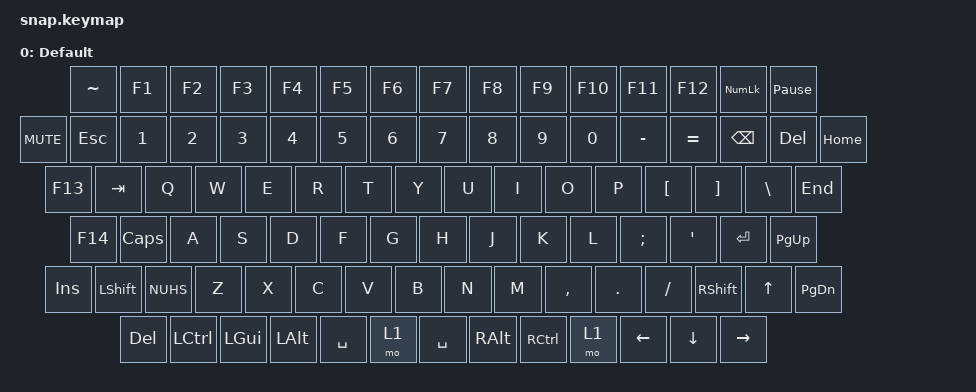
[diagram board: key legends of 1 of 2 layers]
/*
 * Copyright (c) 2022 The ZMK Contributors
 *
 * SPDX-License-Identifier: MIT
 */

#include <behaviors.dtsi>
#include <dt-bindings/zmk/keys.h>
#include <dt-bindings/zmk/rgb.h>
#include <dt-bindings/zmk/rgb.h>

/ {
    sensors {
        compatible = "zmk,keymap-sensors";
        sensors = <&left_encoder &right_encoder>;
    };

      behaviors {
        gresc: grave_escape {
            compatible = "zmk,behavior-mod-morph";
            label = "GRAVE_ESCAPE";
            #binding-cells = <0>;
            bindings = <&kp ESC>, <&kp GRAVE>;
            mods = <(MOD_LGUI|MOD_RGUI)>;
        };
    };

    keymap {
        compatible = "zmk,keymap";

        default_layer {
            label = "Default";
            sensor-bindings = <&inc_dec_kp C_VOL_DN C_VOL_UP>;
            bindings = <
             &kp TILDE &kp F1   &kp F2   &kp F3   &kp F4   &kp F5   &kp F6     &kp F7   &kp F8   &kp F9    &kp F10  &kp F11     &kp F12     &kp KP_NUM   &kp PAUSE_BREAK
&kp C_MUTE   &kp ESC   &kp N1   &kp N2   &kp N3   &kp N4   &kp N5   &kp N6     &kp N7   &kp N8   &kp N9    &kp N0   &kp MINUS   &kp EQUAL   &kp BSPC     &kp DEL    &kp HOME
&kp F13      &kp TAB     &kp Q    &kp W    &kp E    &kp R    &kp T               &kp Y    &kp U    &kp I     &kp O    &kp P       &kp LBKT    &kp RBKT     &kp BSLH   &kp END
&kp F14      &kp CLCK    &kp A    &kp S    &kp D    &kp F             &kp G      &kp H    &kp J    &kp K     &kp L    &kp SEMI    &kp SQT     &kp RET                 &kp PG_UP
&kp INS      &kp LSHFT   &kp NUHS &kp Z    &kp X    &kp C    &kp V    &kp B      &kp N    &kp M    &kp COMMA &kp DOT  &kp FSLH    &kp RSHFT                &kp UP     &kp PG_DN
&kp DEL      &kp LCTRL   &kp LGUI &kp LALT          &kp SPACE         &mo 1      &kp SPACE                   &kp RALT    &kp RCTRL  &mo 1    &kp LEFT     &kp DOWN   &kp RIGHT
            >;
        };

        function_layer {
            label = "Function";
            sensor-bindings = <&inc_dec_kp C_NEXT C_PREV &inc_dec_kp C_NEXT C_PREV>;
            bindings = <
             &bootloader &trans   &trans   &trans   &trans   &trans   &trans     &trans   &trans   &trans   &trans    &trans      &trans      &trans       &bootloader
&kp C_PP     &kp GRAVE   &kp F1   &kp F2   &kp F3   &kp F4   &kp F5   &kp F6     &kp F7   &kp F8   &kp F9    &kp F10  &kp F11     &kp F12     &trans       &trans     &kp C_PP
&trans       &trans      &trans   &trans   &trans   &trans            &trans     &trans   &trans   &trans   &trans    &trans      &trans      &trans       &trans     &trans
&trans       &trans      &trans   &trans   &trans   &trans            &trans     &trans   &trans   &trans   &trans    &trans      &trans                              &trans
&trans       &trans      &trans   &trans   &trans   &trans   &trans   &trans     &trans   &trans   &trans   &trans    &trans      &kp RSHFT                &kp PG_UP  &trans
&trans       &kp LCTRL   &kp LGUI &kp LALT          &kp SPACE         &mo 1      &kp SPACE                  &mo RCTRL &kp RALT    &kp RCTRL   &kp HOME     &kp PG_DN  &kp END
            >;
        };
    };
};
